# HC32M413 register map
File version: 1.0
CPU: CM4 r0p1, little endian, MPU, FPU, 4 interrupt priority bits
Registers are 32-bit, read-write, reset 0x0 unless marked. A register's access mark holds for its fields unless they carry their own. Offsets are from the block's base; [hi:lo] are bit positions; {n}, {i} and the like mark numbered series.

## CRC
Base 0x40050400
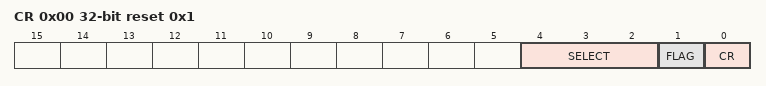
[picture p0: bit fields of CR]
0x00 CR reset 0x1
  [4:2] SELECT, [1] FLAG ro, [0] CR
0x04 RESLT1
0x08 RESLT2
{0x80+4i} DAT{i} wo (i=0..31)

## DBGC
Base 0xE0042000
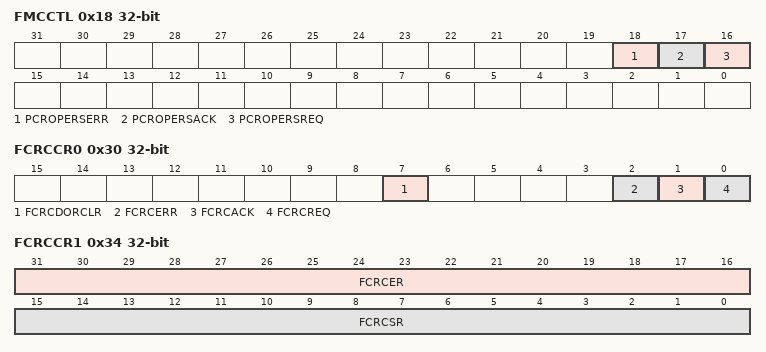
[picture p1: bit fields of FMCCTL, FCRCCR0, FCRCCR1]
0x18 FMCCTL
  [18] PCROPERSERR, [17] PCROPERSACK, [16] PCROPERSREQ
0x30 FCRCCR0
  [7] FCRCDORCLR, [2] FCRCERR, [1] FCRCACK, [0] FCRCREQ
0x34 FCRCCR1
  [31:16] FCRCER, [15:0] FCRCSR
0x38 FCRCDOR ro
0x3C FCRCREF ro

## DCU
Base 0x40052000
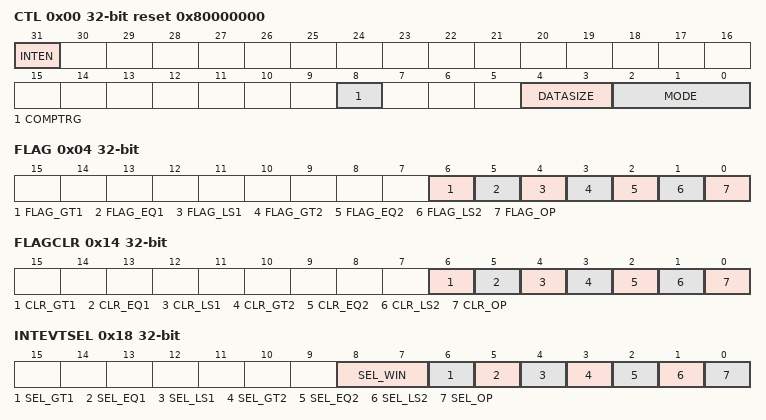
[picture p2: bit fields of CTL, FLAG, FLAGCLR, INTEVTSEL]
0x00 CTL reset 0x80000000
  [31] INTEN, [8] COMPTRG, [4:3] DATASIZE, [2:0] MODE
0x04 FLAG ro
  [6] FLAG_GT1, [5] FLAG_EQ1, [4] FLAG_LS1, [3] FLAG_GT2, [2] FLAG_EQ2, [1] FLAG_LS2, [0] FLAG_OP
{0x8+4i} DATA{i} (i=0..2)
0x14 FLAGCLR wo
  [6] CLR_GT1, [5] CLR_EQ1, [4] CLR_LS1, [3] CLR_GT2, [2] CLR_EQ2, [1] CLR_LS2, [0] CLR_OP
0x18 INTEVTSEL
  [8:7] SEL_WIN, [6] SEL_GT1, [5] SEL_EQ1, [4] SEL_LS1, [3] SEL_GT2, [2] SEL_EQ2, [1] SEL_LS2, [0] SEL_OP

## DMA
Base 0x40053000
0x00 EN
  [0] EN
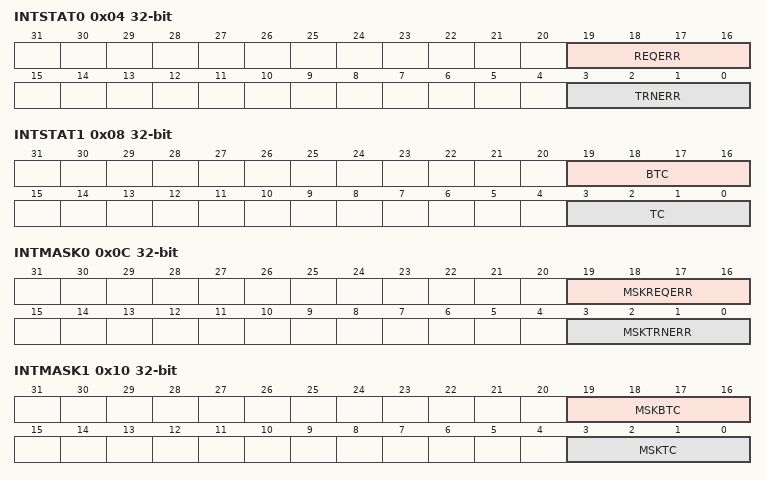
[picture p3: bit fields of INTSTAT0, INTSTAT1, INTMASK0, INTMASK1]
0x04 INTSTAT0 ro
  [19:16] REQERR, [3:0] TRNERR
0x08 INTSTAT1 ro
  [19:16] BTC, [3:0] TC
0x0C INTMASK0
  [19:16] MSKREQERR, [3:0] MSKTRNERR
0x10 INTMASK1
  [19:16] MSKBTC, [3:0] MSKTC
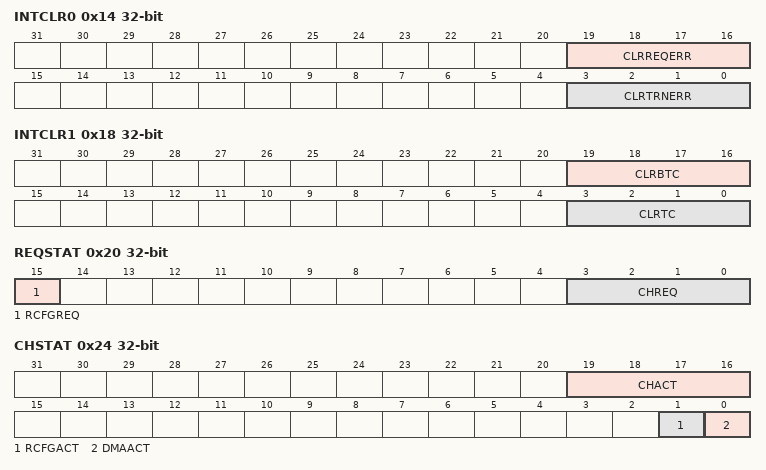
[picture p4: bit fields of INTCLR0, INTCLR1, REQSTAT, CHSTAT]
0x14 INTCLR0
  [19:16] CLRREQERR, [3:0] CLRTRNERR
0x18 INTCLR1
  [19:16] CLRBTC, [3:0] CLRTC
0x1C CHEN
  [3:0] CHEN
0x20 REQSTAT ro
  [15] RCFGREQ, [3:0] CHREQ
0x24 CHSTAT ro
  [19:16] CHACT, [1] RCFGACT, [0] DMAACT
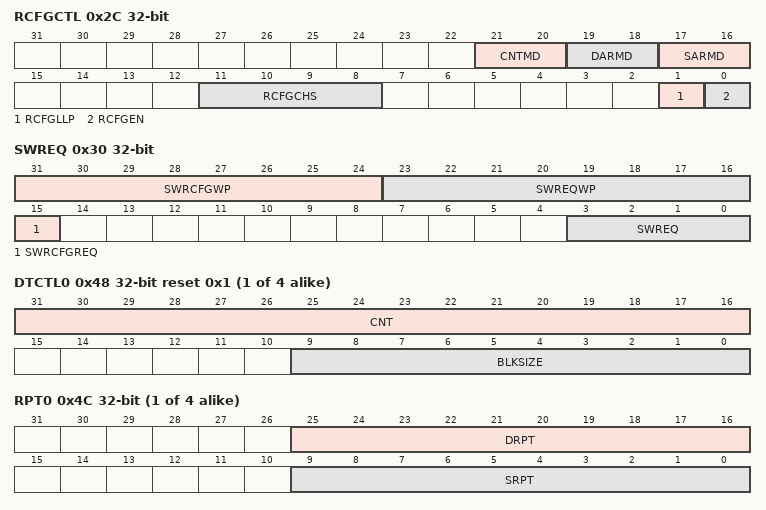
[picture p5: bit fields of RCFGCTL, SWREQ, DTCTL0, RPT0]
0x2C RCFGCTL
  [21:20] CNTMD, [19:18] DARMD, [17:16] SARMD, [11:8] RCFGCHS, [1] RCFGLLP, [0] RCFGEN
0x30 SWREQ wo
  [31:24] SWRCFGWP, [23:16] SWREQWP, [15] SWRCFGREQ, [3:0] SWREQ
0x34 CHENCLR wo
  [3:0] CHENCLR
{0x40+0x40*i} SAR{i} (i=0..3)
{0x44+0x40*i} DAR{i} (i=0..3)
{0x48+0x40*i} DTCTL{i} reset 0x1 (i=0..3)
  [31:16] CNT, [9:0] BLKSIZE
{0x4C+0x40*i} RPT{i} (i=0..3)
  [25:16] DRPT, [9:0] SRPT
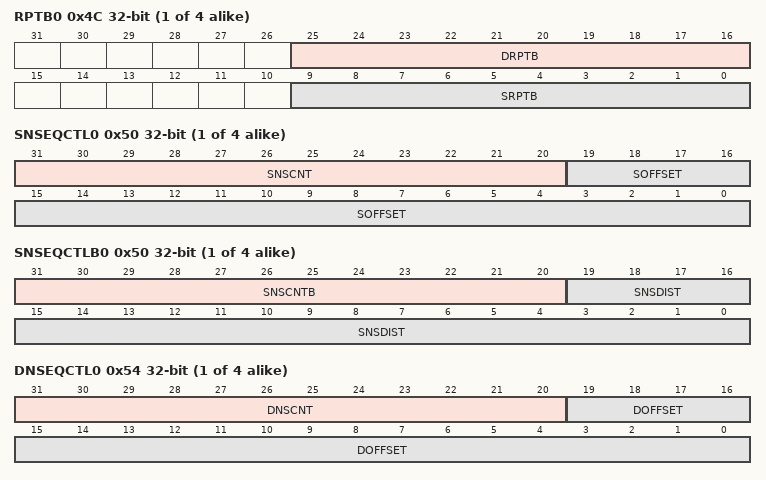
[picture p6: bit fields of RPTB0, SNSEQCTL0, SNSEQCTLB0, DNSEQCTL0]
{0x4C+0x40*i} RPTB{i} (alternate view of RPT{i}) (i=0..3)
  [25:16] DRPTB, [9:0] SRPTB
{0x50+0x40*i} SNSEQCTL{i} (i=0..3)
  [31:20] SNSCNT, [19:0] SOFFSET
{0x50+0x40*i} SNSEQCTLB{i} (alternate view of SNSEQCTL{i}) (i=0..3)
  [31:20] SNSCNTB, [19:0] SNSDIST
{0x54+0x40*i} DNSEQCTL{i} (i=0..3)
  [31:20] DNSCNT, [19:0] DOFFSET
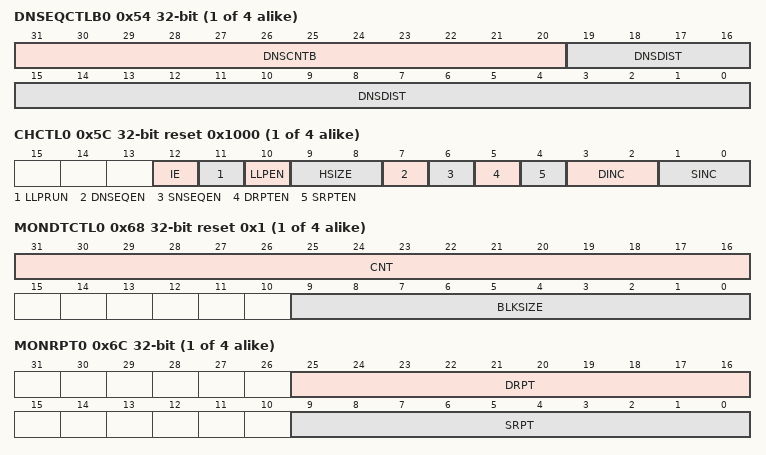
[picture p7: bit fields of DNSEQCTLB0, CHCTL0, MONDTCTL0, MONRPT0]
{0x54+0x40*i} DNSEQCTLB{i} (alternate view of DNSEQCTL{i}) (i=0..3)
  [31:20] DNSCNTB, [19:0] DNSDIST
{0x58+0x40*i} LLP{i} (i=0..3)
  [31:2] LLP
{0x5C+0x40*i} CHCTL{i} reset 0x1000 (i=0..3)
  [12] IE, [11] LLPRUN, [10] LLPEN, [9:8] HSIZE, [7] DNSEQEN, [6] SNSEQEN, [5] DRPTEN, [4] SRPTEN, [3:2] DINC, [1:0] SINC
{0x60+0x40*i} MONSAR{i} ro (i=0..3)
{0x64+0x40*i} MONDAR{i} ro (i=0..3)
{0x68+0x40*i} MONDTCTL{i} ro reset 0x1 (i=0..3)
  [31:16] CNT, [9:0] BLKSIZE
{0x6C+0x40*i} MONRPT{i} ro (i=0..3)
  [25:16] DRPT, [9:0] SRPT
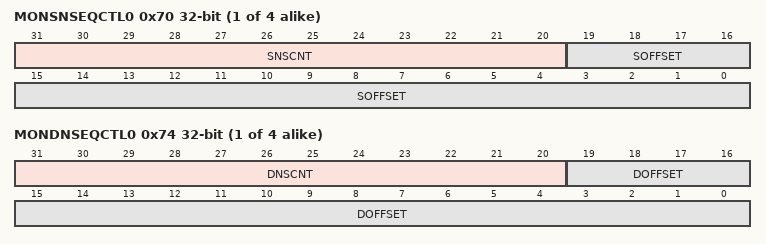
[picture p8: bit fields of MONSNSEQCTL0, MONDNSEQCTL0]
{0x70+0x40*i} MONSNSEQCTL{i} ro (i=0..3)
  [31:20] SNSCNT, [19:0] SOFFSET
{0x74+0x40*i} MONDNSEQCTL{i} ro (i=0..3)
  [31:20] DNSCNT, [19:0] DOFFSET

## EFM
Base 0x40010400
0x00 FAPRT
  [15:0] FAPRT
0x04 FSTP
  [0] FSTP
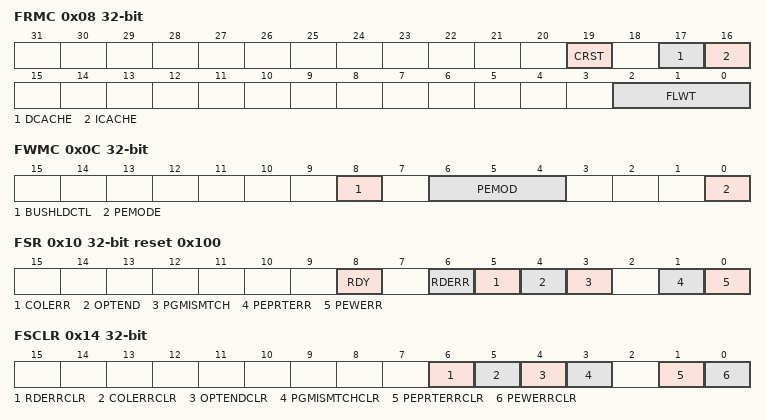
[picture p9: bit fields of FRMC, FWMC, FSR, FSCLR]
0x08 FRMC
  [19] CRST, [17] DCACHE, [16] ICACHE, [2:0] FLWT
0x0C FWMC
  [8] BUSHLDCTL, [6:4] PEMOD, [0] PEMODE
0x10 FSR ro reset 0x100
  [8] RDY, [6] RDERR, [5] COLERR, [4] OPTEND, [3] PGMISMTCH, [1] PEPRTERR, [0] PEWERR
0x14 FSCLR
  [6] RDERRCLR, [5] COLERRCLR, [4] OPTENDCLR, [3] PGMISMTCHCLR, [1] PEPRTERRCLR, [0] PEWERRCLR
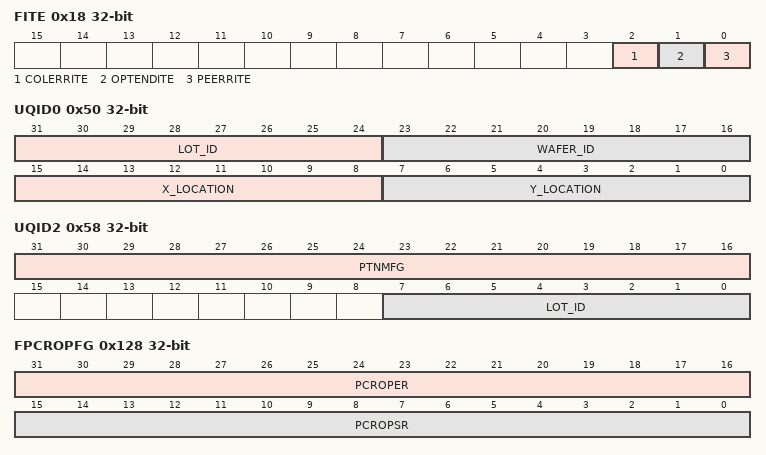
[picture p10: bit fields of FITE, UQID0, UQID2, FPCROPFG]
0x18 FITE
  [2] COLERRITE, [1] OPTENDITE, [0] PEERRITE
0x20 FPMTSW
  [17:0] FPMTSW
0x24 FPMTEW
  [17:0] FPMTEW
0x50 UQID0 ro
  [31:24] LOT_ID, [23:16] WAFER_ID, [15:8] X_LOCATION, [7:0] Y_LOCATION
0x54 UQID1 ro
  [31:0] LOT_ID
0x58 UQID2 ro
  [31:16] PTNMFG, [7:0] LOT_ID
0x70 FOCDPRTFG ro
  [3] PCROPST
0x120 FCRCDOR ro
0x128 FPCROPFG ro
  [31:16] PCROPER, [15:0] PCROPSR
0x288 HRCCFGR 8-bit
  [2:0] HRCFREQS

## EMB0 — desc EMB
Base 0x40017C00
Same registers: EMB1 0x40017C20
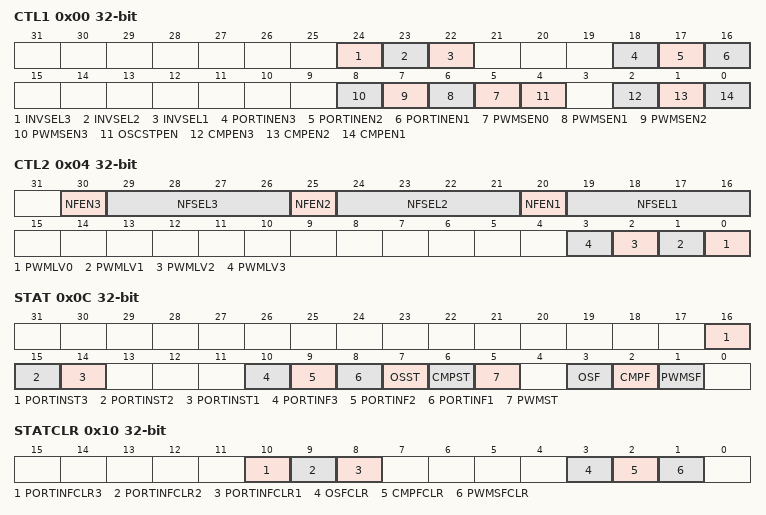
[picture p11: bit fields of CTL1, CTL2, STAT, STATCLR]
0x00 CTL1
  [24] INVSEL3, [23] INVSEL2, [22] INVSEL1, [18] PORTINEN3, [17] PORTINEN2, [16] PORTINEN1, [n+5] PWMSEN{n} (n=0..3), [4] OSCSTPEN, [2] CMPEN3, [1] CMPEN2, [0] CMPEN1
0x04 CTL2
  [30] NFEN3, [29:26] NFSEL3, [25] NFEN2, [24:21] NFSEL2, [20] NFEN1, [19:16] NFSEL1, [n] PWMLV{n} (n=0..3)
0x08 SOE
  [0] SOE
0x0C STAT ro
  [16] PORTINST3, [15] PORTINST2, [14] PORTINST1, [10] PORTINF3, [9] PORTINF2, [8] PORTINF1, [7] OSST, [6] CMPST, [5] PWMST, [3] OSF, [2] CMPF, [1] PWMSF
0x10 STATCLR wo
  [10] PORTINFCLR3, [9] PORTINFCLR2, [8] PORTINFCLR1, [3] OSFCLR, [2] CMPFCLR, [1] PWMSFCLR
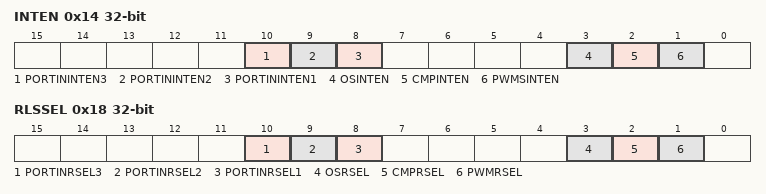
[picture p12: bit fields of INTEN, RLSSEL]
0x14 INTEN
  [10] PORTININTEN3, [9] PORTININTEN2, [8] PORTININTEN1, [3] OSINTEN, [2] CMPINTEN, [1] PWMSINTEN
0x18 RLSSEL
  [10] PORTINRSEL3, [9] PORTINRSEL2, [8] PORTINRSEL1, [3] OSRSEL, [2] CMPRSEL, [1] PWMRSEL
